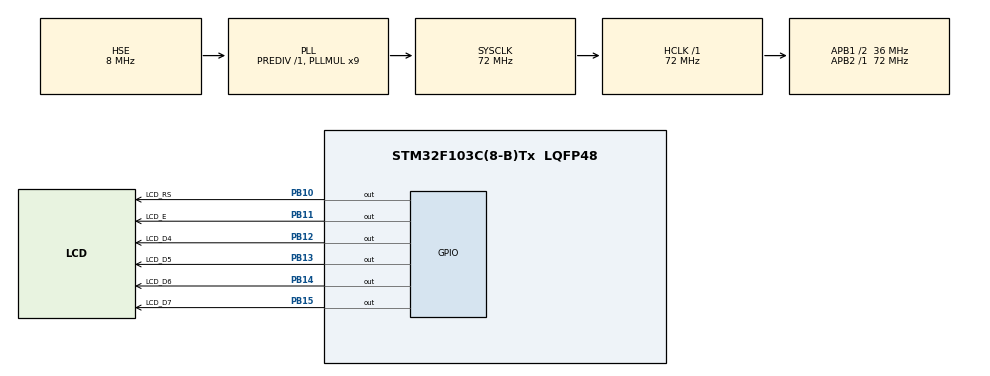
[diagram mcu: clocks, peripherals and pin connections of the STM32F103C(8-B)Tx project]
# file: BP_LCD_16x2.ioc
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Mcu.Family=STM32F1
Mcu.Name=STM32F103C(8-B)Tx
Mcu.Package=LQFP48
NVIC.PriorityGroup=NVIC_PRIORITYGROUP_4
PB10.GPIO_Label=LCD_RS
PB10.GPIO_ModeDefaultOutputPP=GPIO_MODE_OUTPUT_PP
PB10.GPIO_PuPd=GPIO_NOPULL
PB10.GPIO_Speed=GPIO_SPEED_FREQ_HIGH
PB10.PinState=GPIO_PIN_RESET
PB10.Signal=GPIO_Output
PB11.GPIO_Label=LCD_E
PB11.GPIO_ModeDefaultOutputPP=GPIO_MODE_OUTPUT_PP
PB11.GPIO_PuPd=GPIO_NOPULL
PB11.GPIO_Speed=GPIO_SPEED_FREQ_HIGH
PB11.PinState=GPIO_PIN_RESET
PB11.Signal=GPIO_Output
PB12.GPIO_Label=LCD_D4
PB12.GPIO_ModeDefaultOutputPP=GPIO_MODE_OUTPUT_PP
PB12.GPIO_PuPd=GPIO_NOPULL
PB12.GPIO_Speed=GPIO_SPEED_FREQ_HIGH
PB12.PinState=GPIO_PIN_RESET
PB12.Signal=GPIO_Output
PB13.GPIO_Label=LCD_D5
PB13.GPIO_ModeDefaultOutputPP=GPIO_MODE_OUTPUT_PP
PB13.GPIO_PuPd=GPIO_NOPULL
PB13.GPIO_Speed=GPIO_SPEED_FREQ_HIGH
PB13.PinState=GPIO_PIN_RESET
PB13.Signal=GPIO_Output
PB14.GPIO_Label=LCD_D6
PB14.GPIO_ModeDefaultOutputPP=GPIO_MODE_OUTPUT_PP
PB14.GPIO_PuPd=GPIO_NOPULL
PB14.GPIO_Speed=GPIO_SPEED_FREQ_HIGH
PB14.PinState=GPIO_PIN_RESET
PB14.Signal=GPIO_Output
PB15.GPIO_Label=LCD_D7
PB15.GPIO_ModeDefaultOutputPP=GPIO_MODE_OUTPUT_PP
PB15.GPIO_PuPd=GPIO_NOPULL
PB15.GPIO_Speed=GPIO_SPEED_FREQ_HIGH
PB15.PinState=GPIO_PIN_RESET
PB15.Signal=GPIO_Output
PD0-OSC_IN.Mode=HSE-External-Oscillator
PD0-OSC_IN.Signal=RCC_OSC_IN
PD1-OSC_OUT.Mode=HSE-External-Oscillator
PD1-OSC_OUT.Signal=RCC_OSC_OUT
ProjectManager.HeapSize=0x200
ProjectManager.StackSize=0x400
ProjectManager.TargetToolchain=STM32CubeIDE
RCC.AHBFreq_Value=72000000
RCC.APB1CLKDivider=RCC_HCLK_DIV2
RCC.APB1Freq_Value=36000000
RCC.APB1TimFreq_Value=72000000
RCC.APB2Freq_Value=72000000
RCC.APB2TimFreq_Value=72000000
RCC.HCLKFreq_Value=72000000
RCC.PLLMUL=RCC_PLL_MUL9
RCC.PLLSourceVirtual=RCC_PLLSOURCE_HSE
RCC.SYSCLKFreq_VALUE=72000000
RCC.SYSCLKSource=RCC_SYSCLKSOURCE_PLLCLK
RCC.USBFreq_Value=72000000
VP_SYS_VS_ND.Mode=No_Debug
board=custom

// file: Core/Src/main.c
/* USER CODE BEGIN Header */
/**
  ******************************************************************************
  * @file           : main.c
  * @brief          : Main program body
  ******************************************************************************
  * @attention
  *
  * Copyright (c) 2025 STMicroelectronics.
  * All rights reserved.
  *
  * This software is licensed under terms that can be found in the LICENSE file
  * in the root directory of this software component.
  * If no LICENSE file comes with this software, it is provided AS-IS.
  *
  ******************************************************************************
  */
/* USER CODE END Header */
#include "main.h"
#include "main.h"
#include "stm32f1xx_hal.h"
#include "LCD16X2.h"
#include "stdio.h"
#include "string.h"
#include "number2string.h"
#define MyLCD LCD16X2_1
void SystemClock_Config(void);
static void MX_GPIO_Init(void);

void SystemClock_Config(void);
static void MX_GPIO_Init(void);

int main(void)
{

  /* MCU Configuration--------------------------------------------------------*/

  /* Reset of all peripherals, Initializes the Flash interface and the Systick. */
  HAL_Init();

  /* USER CODE BEGIN Init */
  	char buffer[20];

    float number = 12.345;

  /* USER CODE END Init */

  /* Configure the system clock */
  SystemClock_Config();

  /* Initialize all configured peripherals */
  MX_GPIO_Init();
  /* USER CODE BEGIN 2 */
  LCD16X2_Init(MyLCD);
   LCD16X2_Clear(MyLCD);
   LCD16X2_Set_Cursor(MyLCD, 1, 1);
   LCD16X2_Write_String(MyLCD, "PROF Mozart");
   FloatToStr(number, buffer, 3);
   LCD16X2_Set_Cursor(MyLCD, 2, 1);
   LCD16X2_Write_String(MyLCD, buffer);

  HAL_Delay(5000);

  /* USER CODE END 2 */

  /* Infinite loop */
  /* USER CODE BEGIN WHILE */
  while (1)
  {
	  for(int i=0;i<=50;i++)
	    {
		  LCD16X2_Clear(MyLCD);
	      LCD16X2_Set_Cursor(MyLCD, 1, 1);
	      LCD16X2_Write_String(MyLCD, "Contador = ");
	      IntToStr(i, buffer, 10);
	      LCD16X2_Set_Cursor(MyLCD, 1, 12);
	      LCD16X2_Write_String(MyLCD, buffer);
	      HAL_Delay(500);
	    }
  }
  /* USER CODE END 3 */
}

void SystemClock_Config(void)
{
  RCC_OscInitTypeDef RCC_OscInitStruct = {0};
  RCC_ClkInitTypeDef RCC_ClkInitStruct = {0};

  /** Initializes the RCC Oscillators according to the specified parameters
  * in the RCC_OscInitTypeDef structure.
  */
  RCC_OscInitStruct.OscillatorType = RCC_OSCILLATORTYPE_HSE;
  RCC_OscInitStruct.HSEState = RCC_HSE_ON;
  RCC_OscInitStruct.HSEPredivValue = RCC_HSE_PREDIV_DIV1;
  RCC_OscInitStruct.HSIState = RCC_HSI_ON;
  RCC_OscInitStruct.PLL.PLLState = RCC_PLL_ON;
  RCC_OscInitStruct.PLL.PLLSource = RCC_PLLSOURCE_HSE;
  RCC_OscInitStruct.PLL.PLLMUL = RCC_PLL_MUL9;
  if (HAL_RCC_OscConfig(&RCC_OscInitStruct) != HAL_OK)
  {
    Error_Handler();
  }

  /** Initializes the CPU, AHB and APB buses clocks
  */
  RCC_ClkInitStruct.ClockType = RCC_CLOCKTYPE_HCLK|RCC_CLOCKTYPE_SYSCLK
                              |RCC_CLOCKTYPE_PCLK1|RCC_CLOCKTYPE_PCLK2;
  RCC_ClkInitStruct.SYSCLKSource = RCC_SYSCLKSOURCE_PLLCLK;
  RCC_ClkInitStruct.AHBCLKDivider = RCC_SYSCLK_DIV1;
  RCC_ClkInitStruct.APB1CLKDivider = RCC_HCLK_DIV2;
  RCC_ClkInitStruct.APB2CLKDivider = RCC_HCLK_DIV1;

  if (HAL_RCC_ClockConfig(&RCC_ClkInitStruct, FLASH_LATENCY_2) != HAL_OK)
  {
    Error_Handler();
  }
}

static void MX_GPIO_Init(void)
{
  GPIO_InitTypeDef GPIO_InitStruct = {0};

  /* GPIO Ports Clock Enable */
  __HAL_RCC_GPIOD_CLK_ENABLE();
  __HAL_RCC_GPIOB_CLK_ENABLE();

  /*Configure GPIO pin Output Level */
  HAL_GPIO_WritePin(GPIOB, LCD_RS_Pin|LCD_E_Pin|LCD_D4_Pin|LCD_D5_Pin
                          |LCD_D6_Pin|LCD_D7_Pin, GPIO_PIN_RESET);

  /*Configure GPIO pins : LCD_RS_Pin LCD_E_Pin LCD_D4_Pin LCD_D5_Pin
                           LCD_D6_Pin LCD_D7_Pin */
  GPIO_InitStruct.Pin = LCD_RS_Pin|LCD_E_Pin|LCD_D4_Pin|LCD_D5_Pin
                          |LCD_D6_Pin|LCD_D7_Pin;
  GPIO_InitStruct.Mode = GPIO_MODE_OUTPUT_PP;
  GPIO_InitStruct.Pull = GPIO_NOPULL;
  GPIO_InitStruct.Speed = GPIO_SPEED_FREQ_HIGH;
  HAL_GPIO_Init(GPIOB, &GPIO_InitStruct);

}

void Error_Handler(void)
{
  __disable_irq();
  while (1)
  {
  }
}
